# Template register map
Vendor: VendorName Co.Ltd; Series: SeriesName; File version: 1.2
CPU: CM7 r0p1, little endian, MPU, FPU, 4 interrupt priority bits
Registers are 32-bit, read-write, no defined reset value unless marked. A register's access mark holds for its fields unless they carry their own. Offsets are from the block's base; [hi:lo] are bit positions.

## SRAM — On-Chip SRAM
Base 0x400B2000
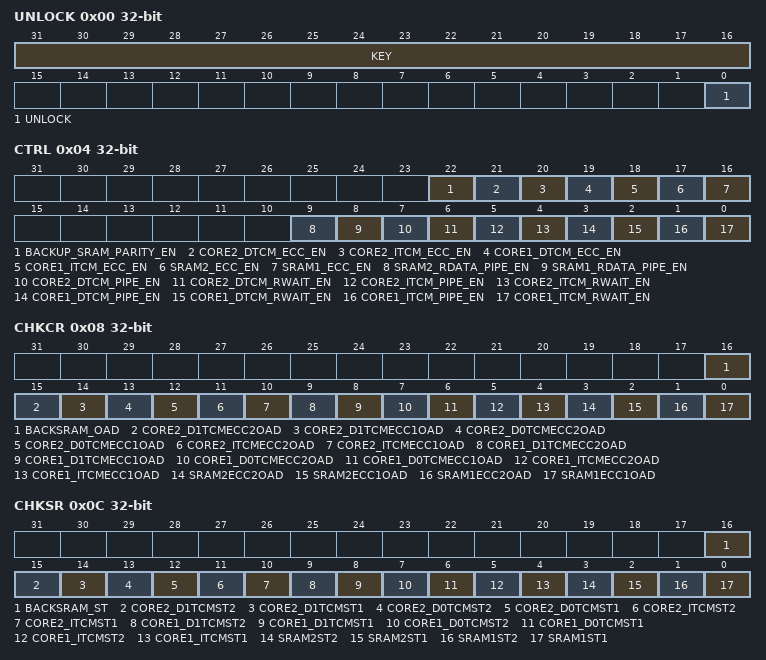
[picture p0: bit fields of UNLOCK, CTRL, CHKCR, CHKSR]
0x00 UNLOCK — SRAM protection unlock register
  [31:16] KEY wo — SRAM KEY[15:0] bit: only when 0x695A is written at high position can this register be written
  [0] UNLOCK — SRAM UNLOCK bit: SRAM control register writing unlock
0x04 CTRL — SRAM control register
  [22] BACKUP_SRAM_PARITY_EN — SRAM BACKUP_SRAM_PARITY_EN bit: backup SRAM parity enable
  [21] CORE2_DTCM_ECC_EN — SRAM CORE2_DTCM_ECC_EN bit: CORE2 DTCM ECC enable
  [20] CORE2_ITCM_ECC_EN — SRAM CORE2_ITCM_ECC_EN bit: CORE2 ITCM ECC enable
  [19] CORE1_DTCM_ECC_EN — SRAM CORE1_DTCM_ECC_EN bit: CORE1 DTCM ECC enable
  [18] CORE1_ITCM_ECC_EN — SRAM CORE1_ITCM_ECC_EN bit: CORE1 ITCM ECC enable
  [17] SRAM2_ECC_EN — SRAM SRAM2_ECC_EN bit: SRAM2 ECC enable
  [16] SRAM1_ECC_EN — SRAM SRAM1_ECC_EN bit: SRAM1 ECC enable
  [9] SRAM2_RDATA_PIPE_EN — SRAM SRAM2_RDATA_PIPE_EN bit: SRAM2 read data channel address pipe enable
  [8] SRAM1_RDATA_PIPE_EN — SRAM SRAM1_RDATA_PIPE_EN bit: SRAM1 read data channel address pipe enable
  [7] CORE2_DTCM_PIPE_EN — SRAM CORE2_DTCM_PIPE_EN bit: CORE2 DTCM pipe read enable
  [6] CORE2_DTCM_RWAIT_EN — SRAM CORE2_DTCM_RWAIT_EN bit: CORE2 DTCM read period selection control
  [5] CORE2_ITCM_PIPE_EN — SRAM CORE2_ITCM_PIPE_EN bit: CORE2 ITCM pipe read enable
  [4] CORE2_ITCM_RWAIT_EN — SRAM CORE2_ITCM_RWAIT_EN bit: CORE2 ITCM read period selection control
  [3] CORE1_DTCM_PIPE_EN — SRAM CORE1_DTCM_PIPE_EN bit: CORE1 DTCM pipe read enable
  [2] CORE1_DTCM_RWAIT_EN — SRAM CORE1_DTCM_RWAIT_EN bit: CORE1 DTCM read period selection control
  [1] CORE1_ITCM_PIPE_EN — SRAM CORE1_ITCM_PIPE_EN bit: CORE1 ITCM pipe read enable
  [0] CORE1_ITCM_RWAIT_EN — SRAM CORE1_ITCM_RWAIT_EN bit: CORE1 ITCM read period selection control
0x08 CHKCR — SRAM check control register
  [16] BACKSRAM_OAD — SRAM BACKSRAM_OAD bit: operation after BACKSRAM generate parity check error detection
  [15] CORE2_D1TCMECC2OAD — SRAM CORE2_D1TCMECC2OAD bit: operation after CORE2 D1TCM generate ECC check 2 bits error detection
  [14] CORE2_D1TCMECC1OAD — SRAM CORE2_D1TCMECC1OAD bit: operation after CORE2 D1TCM generate ECC check 1 bit error detection
  [13] CORE2_D0TCMECC2OAD — SRAM CORE2_D0TCMECC2OAD bit: operation after CORE2 D0TCM generate ECC check 2 bits error detection
  [12] CORE2_D0TCMECC1OAD — SRAM CORE2_D0TCMECC1OAD bit: operation after CORE2 D0TCM generate ECC check 1 bit error detection
  [11] CORE2_ITCMECC2OAD — SRAM CORE2_ITCMECC2OAD bit: operation after CORE2 ITCM generate ECC check 2 bits error detection
  [10] CORE2_ITCMECC1OAD — SRAM CORE2_ITCMECC1OAD bit: operation after CORE2 ITCM generate ECC check 1 bit error detection
  [9] CORE1_D1TCMECC2OAD — SRAM CORE1_D1TCMECC2OAD bit: operation after CORE1 D1TCM generate ECC check 2 bits error detection
  [8] CORE1_D1TCMECC1OAD — SRAM CORE1_D1TCMECC1OAD bit: operation after CORE1 D1TCM generate ECC check 1 bit error detection
  [7] CORE1_D0TCMECC2OAD — SRAM CORE1_D0TCMECC2OAD bit: operation after CORE1 D0TCM generate ECC check 2 bits error detection
  [6] CORE1_D0TCMECC1OAD — SRAM CORE1_D0TCMECC1OAD bit: operation after CORE1 D0TCM generate ECC check 1 bit error detection
  [5] CORE1_ITCMECC2OAD — SRAM CORE1_ITCMECC2OAD bit: operation after CORE1 ITCM generate ECC check 2 bits error detection
  [4] CORE1_ITCMECC1OAD — SRAM CORE1_ITCMECC1OAD bit: operation after CORE1 ITCM generate ECC check 1 bit error detection
  [3] SRAM2ECC2OAD — SRAM SRAM2ECC2OAD bit: operation after SRAM2 generate ECC check 2 bits error detection
  [2] SRAM2ECC1OAD — SRAM SRAM2ECC1OAD bit: operation after SRAM2 generate ECC check 1 bit error detection
  [1] SRAM1ECC2OAD — SRAM SRAM1ECC2OAD bit: operation after SRAM1 generate ECC check 2 bits error detection
  [0] SRAM1ECC1OAD — SRAM SRAM1ECC1OAD bit: operation after SRAM1 generate ECC check 1 bit error detection
0x0C CHKSR — SRAM error status register
  [16] BACKSRAM_ST — SRAM BACKSRAM_ST bit: BACKSRAM parity check error flag bit
  [15] CORE2_D1TCMST2 — SRAM CORE2_D1TCMST2 bit: CORE2 D1TCM ECC check error flag bit 2
  [14] CORE2_D1TCMST1 — SRAM CORE2_D1TCMST1 bit: CORE2 D1TCM ECC check error flag bit 1
  [13] CORE2_D0TCMST2 — SRAM CORE2_D0TCMST2 bit: CORE2 D0TCM ECC check error flag bit 2
  [12] CORE2_D0TCMST1 — SRAM CORE2_D0TCMST1 bit: CORE2 D0TCM ECC check error flag bit 1
  [11] CORE2_ITCMST2 — SRAM CORE2_ITCMST2 bit: CORE2 ITCM ECC check error flag bit 2
  [10] CORE2_ITCMST1 — SRAM CORE2_ITCMST1 bit: CORE2 ITCM ECC check error flag bit 1
  [9] CORE1_D1TCMST2 — SRAM CORE1_D1TCMST2 bit: CORE1 D1TCM ECC check error flag bit 2
  [8] CORE1_D1TCMST1 — SRAM CORE1_D1TCMST1 bit: CORE1 D1TCM ECC check error flag bit 1
  [7] CORE1_D0TCMST2 — SRAM CORE1_D0TCMST2 bit: CORE1 D0TCM ECC check error flag bit 2
  [6] CORE1_D0TCMST1 — SRAM CORE1_D0TCMST1 bit: CORE1 D0TCM ECC check error flag bit 1
  [5] CORE1_ITCMST2 — SRAM CORE1_ITCMST2 bit: CORE1 ITCM ECC check error flag bit 2
  [4] CORE1_ITCMST1 — SRAM CORE1_ITCMST1 bit: CORE1 ITCM ECC check error flag bit 1
  [3] SRAM2ST2 — SRAM SRAM2ST2 bit: SRAM2 ECC check error flag bit 2
  [2] SRAM2ST1 — SRAM SRAM2ST1 bit: SRAM2 ECC check error flag bit 1
  [1] SRAM1ST2 — SRAM SRAM1ST2 bit: SRAM1 ECC check error flag bit 2
  [0] SRAM1ST1 — SRAM SRAM1ST1 bit: SRAM1 ECC check error flag bit 1
0x10 SRAM1_ECC_ERR_ADDR ro — SRAM1 ECC error address register
  [31:0] SRAM1_ECC_ERR_ADDR — SRAM SRAM1_ECC_ERR_ADDR[31:0] bit: SRAM1 ECC error address
0x14 SRAM2_ECC_ERR_ADDR ro — SRAM2 ECC error address register
  [31:0] SRAM2_ECC_ERR_ADDR — SRAM SRAM2_ECC_ERR_ADDR[31:0] bit: SRAM2 ECC error address
0x18 CORE1_ITCM_ECC_ERR_ADDR ro — SRAM CORE1 ITCM ECC error address register
  [31:0] ITCM_ECC_ERR_ADDR — SRAM ITCM_ECC_ERR_ADDR[31:0] bit: CORE1 ITCM ECC error address
0x1C CORE1_D0TCM_ECC_ERR_ADDR ro — SRAM CORE1 D0TCM ECC error address register
  [31:0] D0TCM_ECC_ERR_ADDR — SRAM D0TCM_ECC_ERR_ADDR[31:0] bit: CORE1 D0TCM ECC error address
0x20 CORE1_D1TCM_ECC_ERR_ADDR ro — SRAM CORE1 D1TCM ECC error address register
  [31:0] D1TCM_ECC_ERR_ADDR — SRAM D1TCM_ECC_ERR_ADDR[31:0] bit: CORE1 D1TCM ECC error address
0x24 CORE2_ITCM_ECC_ERR_ADDR ro — SRAM CORE2 ITCM ECC error address register
  [31:0] ITCM_ECC_ERR_ADDR — SRAM ITCM_ECC_ERR_ADDR[31:0] bit: CORE2 ITCM ECC error address
0x28 CORE2_D0TCM_ECC_ERR_ADDR ro — SRAM CORE2 D0TCM ECC error address register
  [31:0] D0TCM_ECC_ERR_ADDR — SRAM D0TCM_ECC_ERR_ADDR[31:0] bit: CORE2 D0TCM ECC error address
0x2C CORE2_D1TCM_ECC_ERR_ADDR ro — SRAM CORE2 D1TCM ECC error address register
  [31:0] D1TCM_ECC_ERR_ADDR — SRAM D1TCM_ECC_ERR_ADDR[31:0] bit: CORE2 D1TCM ECC error address
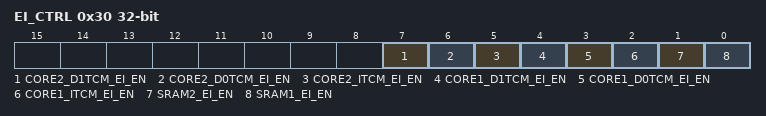
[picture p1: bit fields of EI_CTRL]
0x30 EI_CTRL — SRAM ECC error inject control register
  [7] CORE2_D1TCM_EI_EN — SRAM CORE2_D1TCM_EI_EN bit: CORE2 D1TCM ECC error inject enable
  [6] CORE2_D0TCM_EI_EN — SRAM CORE2_D0TCM_EI_EN bit: CORE2 D0TCM ECC error inject enable
  [5] CORE2_ITCM_EI_EN — SRAM CORE2_ITCM_EI_EN bit: CORE2 ITCM ECC error inject enable
  [4] CORE1_D1TCM_EI_EN — SRAM CORE1_D1TCM_EI_EN bit: CORE1 D1TCM ECC error inject enable
  [3] CORE1_D0TCM_EI_EN — SRAM CORE1_D0TCM_EI_EN bit: CORE1 D0TCM ECC error inject enable
  [2] CORE1_ITCM_EI_EN — SRAM CORE1_ITCM_EI_EN bit: CORE1 ITCM ECC error inject enable
  [1] SRAM2_EI_EN — SRAM SRAM2_EI_EN bit: SRAM2 ECC error inject enable
  [0] SRAM1_EI_EN — SRAM SRAM1_EI_EN bit: SRAM1 ECC error inject enable
0x34 EI_DM_LOW — SRAM ECC error inject data MASK low 32 bits register
  [31:0] SRAM_EI_DM_LOW — SRAM SRAM_EI_DM_LOW[31:0] bit: inverse corrspondig bit of writing data of SRAM low 32 bits
0x38 EI_DM_HIGH — SRAM ECC error inject data MASK high 32 bits register
  [31:0] SRAM_EI_DM_HIGH — SRAM SRAM_EI_DM_HIGH[31:0] bit: inverse corrspondig bit of writing data of SRAM high 32 bits
0x3C EI_CHK — SRAM ECC error inject check bit MASK register
  [7:0] SRAM_EI_CHK — SRAM SRAM_EI_CHK[7:0] bit: inverse corrsponding bit of SRAM ECC check data
0x40 ITCM_EI_DM_LOW — SRAM ITCM ECC error inject data MASK low 32 bits register
  [31:0] ITCM_EI_DM_LOW — SRAM ITCM_EI_DM_LOW[31:0] bit: inverse corrspondig bit of writing data of ITCM low 32 bits
0x44 ITCM_EI_DM_HIGH — SRAM ITCM ECC error inject data MASK high 32 bits register
  [31:0] ITCM_EI_DM_HIGH — SRAM ITCM_EI_DM_HIGH[31:0] bit: inverse corrspondig bit of writing data of ITCM high 32 bits
0x48 ITCM_EI_CHK — SRAM ITCM ECC error inject check bit MASK register
  [7:0] ITCM_EI_CHK — SRAM ITCM_EI_CHK[7:0] bit: inverse corrsponding bit of ITCM ECC check data
0x4C D0TCM_EI_DM — SRAM D0TCM ECC error inject data MASK register
  [31:0] D0TCM_EI_DM — SRAM D0TCM_EI_DM[31:0] bit: inverse corrsponding bit of writing data of D0TCM
0x50 D0TCM_EI_CHK — SRAM D0TCM ECC error inject check bit MASK register
  [31:7] D0TCM_EI_CHK — SRAM D0TCM_EI_CHK[24:0] bit: inverse corrsponding bit of D0CTM ECC check data
0x54 D1TCM_EI_DM — SRAM D1TCM ECC error inject data MASK register
  [31:0] D1TCM_EI_DM — SRAM D1TCM_EI_DM[31:0] bit: inverse corrsponding bit of writing data of D1TCM
0x58 D1TCM_EI_CHK — SRAM D1TCM ECC error inject check bit MASK register
  [6:0] D1TCM_EI_CHK — SRAM D1TCM_EI_CHK[6:0] bit: inverse corrsponding bit of D1CTM ECC check data
